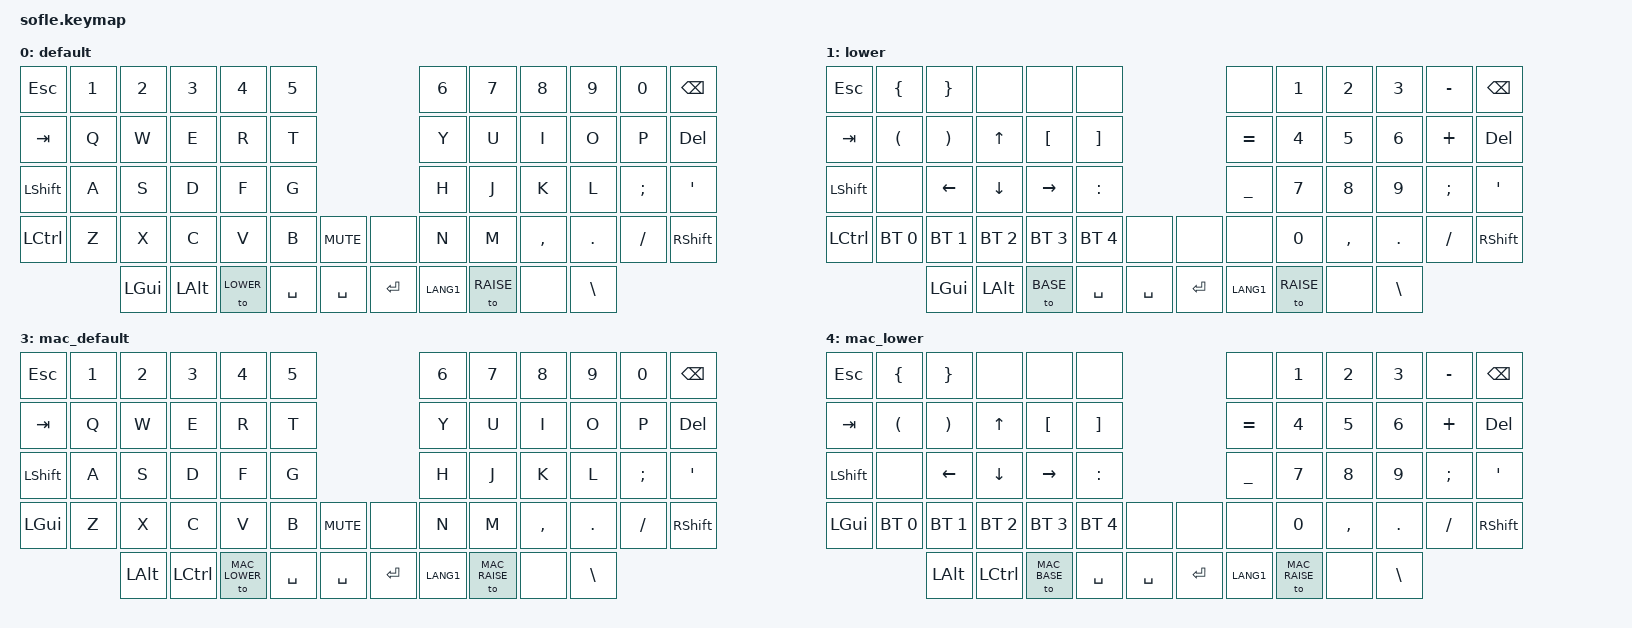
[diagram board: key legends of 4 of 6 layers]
/*
 * Copyright (c) 2020 The ZMK Contributors
 *
 * SPDX-License-Identifier: MIT
 */

#include <behaviors.dtsi>
#include <dt-bindings/zmk/keys.h>
#include <dt-bindings/zmk/bt.h>
#include <dt-bindings/zmk/rgb.h>
#include <dt-bindings/zmk/ext_power.h>

#define BASE 0
#define LOWER 1
#define RAISE 2
#define MAC_BASE 3
#define MAC_LOWER 4
#define MAC_RAISE 5


/ {

   // Activate ADJUST layer by pressing raise and lower
   //conditional_layers {
   //   compatible = "zmk,conditional-layers";
   //   adjust_layer {
   //       if-layers = <LOWER RAISE>;
   //       then-layer = <ADJUST>;
   //   };
   //};

    keymap {
        compatible = "zmk,keymap";

        default_layer {
            display-name = "default";
// ------------------------------------------------------------------------------------------------------------
// |  ESC  |  1  |  2  |  3   |  4   |  5   |                   |  6   |  7    |  8    |  9   |   0   | BKSPC |
// |  TAB  |  Q  |  W  |  E   |  R   |  T   |                   |  Y   |  U    |  I    |  O   |   P   |  DEL  |
// | SHIFT |  A  |  S  |  D   |  F   |  G   |                   |  H   |  J    |  K    |  L   |   ;   |   '   |
// | CTRL  |  Z  |  X  |  C   |  V   |  B   |  MUTE  |  |       |  N   |  M    |  , <  |  . > |   /   | SHIFT |
//               | GUI | ALT  | LOWER| SPACE|  SPACE |  | ENTER | Lang | RAISE |       |  \   |
            bindings = <
&kp ESC   &kp N1 &kp N2   &kp N3   &kp N4    &kp N5                           &kp N6 &kp N7    &kp N8    &kp N9   &kp N0   &kp BSPC
&kp TAB   &kp Q  &kp W    &kp E    &kp R     &kp T                            &kp Y  &kp U     &kp I     &kp O    &kp P    &kp DEL
&kp LSHFT &kp A  &kp S    &kp D    &kp F     &kp G                            &kp H  &kp J     &kp K     &kp L    &kp SEMI &kp SQT
&kp LCTRL &kp Z  &kp X    &kp C    &kp V     &kp B      &kp C_MUTE &none      &kp N  &kp M     &kp COMMA &kp DOT  &kp FSLH &kp RSHFT
                 &kp LGUI &kp LALT &to LOWER &kp SPACE  &kp SPACE  &kp RET    &kp LANG1 &to RAISE &none  &kp BSLH
            >;

            sensor-bindings = <&inc_dec_kp C_VOL_UP C_VOL_DN &inc_dec_kp PG_UP PG_DN>;  
        };

        lower_layer {
            display-name = "lower";
// ------------------------------------------------------------------------------------------------------------
// |  ESC  |  {  |  }  |      |      |      |                   |      |  1    |  2    |  3   |   −   | BKSPC |
// |  TAB  |  (  |  )  |  UP  |  [   |  ]   |                   |  =   |  4    |  5    |  6   |   +   | DEL   |
// | SHIFT |     | LEFT| DOWN |RIGHT |  :   |                   |  _   |  7    |  8    |  9   |   ;   |   '   |
// | CTRL  | BT1 | BT2 | BT3  | BT4  | BT5  |        |  |       |      |  0    |  ,    |  .   |   /   | SHIFT |
//               | GUI | ALT  | BASE | SPACE| SPACE  |  | ENTER | Lang | RAISE |       |  \   |
             bindings = <
&kp ESC    &kp LBRC     &kp RBRC     &none        &none        &none                                &none     &kp N1   &kp N2          &kp N3    &kp MINUS &kp BSPC
&kp TAB    &kp LPAR     &kp RPAR     &kp UP       &kp LBKT     &kp RBKT                             &kp EQUAL &kp N4   &kp N5          &kp N6    &kp PLUS  &kp DEL
&kp LSHFT  &none        &kp LEFT     &kp DOWN     &kp RIGHT    &kp COLON                            &kp UNDER &kp N7   &kp N8          &kp N9    &kp SEMI  &kp SQT
&kp LCTRL  &bt BT_SEL 0 &bt BT_SEL 1 &bt BT_SEL 2 &bt BT_SEL 3 &bt BT_SEL 4   &none  &none          &none     &kp N0   &kp COMMA       &kp DOT   &kp FSLH  &kp RSHFT
                 &kp LGUI &kp LALT &to BASE &kp SPACE  &kp SPACE                          &kp RET   &kp LANG1 &to RAISE&none           &kp BSLH
            >;

            sensor-bindings = <&inc_dec_kp C_VOL_UP C_VOL_DN &inc_dec_kp PG_UP PG_DN>;
        };

        raise_layer {
            display-name = "raise";
// ------------------------------------------------------------------------------------------------------------
// |  ESC  |  F1  |  F2  |  F3   |  F4   |  F5  |                |  F6  |  F7    |  F8   |  F9  |  F10  | BKSPC |
// | CAPS  | INS  | HOME | PGUP  |  F11  |  F12 |                |      |        |       |      |       |  DEL  |
// | SHIFT | DEL  | END  | PGDN  |       |      |                |      |        |       |      |       |       |
// | CTRL  | UNDO | CUT  | COPY  | PASTE |      |      |  |      | BTCLR|MAC BASE|       |      |       |       |
//                | GUI  |  ALT  | LOWER | SPACE| SPACE|  | ENTER| Lang | BASE   |       |      |
            bindings = <
&kp ESC    &kp F1       &kp F2       &kp F3       &kp F4       &kp F5                        &kp F6    &kp F7       &kp F8    &kp F9    &kp F10   &kp BSPC
&kp CAPS   &kp INS      &kp HOME     &kp PGUP     &kp F11      &kp F12                       &none     &none        &none     &none     &none     &kp DEL
&kp LSHFT  &kp DEL      &kp END      &kp PGDN     &none        &none                         &none     &none        &none     &none     &none     &none
&kp LCTRL  &kp K_UNDO   &kp K_CUT    &kp K_COPY   &kp K_PASTE  &none         &none   &none   &bt BT_CLR&to MAC_BASE &none     &none     &none     &none
                        &kp LGUI     &kp LALT     &to LOWER    &kp SPACE   &kp SPACE &kp RET &kp LANG1 &to BASE     &none     &none     &none
            >;

            sensor-bindings = <&inc_dec_kp C_VOL_UP C_VOL_DN &inc_dec_kp PG_UP PG_DN>;
        };



        mac_default_layer {
            display-name = "mac_default";
// ------------------------------------------------------------------------------------------------------------
// |  ESC  |  1  |  2  |  3   |  4   |  5   |                   |  6   |  7    |  8    |  9   |   0   | BKSPC |
// |  TAB  |  Q  |  W  |  E   |  R   |  T   |                   |  Y   |  U    |  I    |  O   |   P   |  DEL  |
// | SHIFT |  A  |  S  |  D   |  F   |  G   |                   |  H   |  J    |  K    |  L   |   ;   |   '   |
// | CTRL  |  Z  |  X  |  C   |  V   |  B   |  MUTE  |  |       |  N   |  M    |  , <  |  . > |   /   | SHIFT |
//               | GUI | ALT  | LOWER| SPACE|  SPACE |  | ENTER | Lang | RAISE |       |  \   |
            bindings = <
&kp ESC   &kp N1 &kp N2   &kp N3   &kp N4    &kp N5                           &kp N6 &kp N7    &kp N8    &kp N9   &kp N0   &kp BSPC
&kp TAB   &kp Q  &kp W    &kp E    &kp R     &kp T                            &kp Y  &kp U     &kp I     &kp O    &kp P    &kp DEL
&kp LSHFT &kp A  &kp S    &kp D    &kp F     &kp G                            &kp H  &kp J     &kp K     &kp L    &kp SEMI &kp SQT
&kp LGUI &kp Z  &kp X    &kp C    &kp V     &kp B      &kp C_MUTE &none      &kp N  &kp M     &kp COMMA &kp DOT  &kp FSLH &kp RSHFT
                 &kp LALT &kp LCTRL &to MAC_LOWER &kp SPACE  &kp SPACE  &kp RET    &kp LANG1 &to MAC_RAISE &none  &kp BSLH
            >;

            sensor-bindings = <&inc_dec_kp C_VOL_UP C_VOL_DN &inc_dec_kp PG_UP PG_DN>;  
        };

        mac_lower_layer {
            display-name = "mac_lower";
// ------------------------------------------------------------------------------------------------------------
// |  ESC  |  {  |  }  |      |      |      |                   |      |  1    |  2    |  3   |   −   | BKSPC |
// |  TAB  |  (  |  )  |  UP  |  [   |  ]   |                   |  =   |  4    |  5    |  6   |   +   | DEL   |
// | SHIFT |     | LEFT| DOWN |RIGHT |  :   |                   |  _   |  7    |  8    |  9   |   ;   |   '   |
// | CTRL  | BT1 | BT2 | BT3  | BT4  | BT5  |        |  |       |      |  0    |  ,    |  .   |   /   | SHIFT |
//               | GUI | ALT  | BASE | SPACE| SPACE  |  | ENTER | Lang | RAISE |       |  \   |
             bindings = <
&kp ESC    &kp LBRC     &kp RBRC     &none        &none        &none                                &none     &kp N1   &kp N2          &kp N3    &kp MINUS &kp BSPC
&kp TAB    &kp LPAR     &kp RPAR     &kp UP       &kp LBKT     &kp RBKT                             &kp EQUAL &kp N4   &kp N5          &kp N6    &kp PLUS  &kp DEL
&kp LSHFT  &none        &kp LEFT     &kp DOWN     &kp RIGHT    &kp COLON                            &kp UNDER &kp N7   &kp N8          &kp N9    &kp SEMI  &kp SQT
&kp LGUI  &bt BT_SEL 0 &bt BT_SEL 1 &bt BT_SEL 2 &bt BT_SEL 3 &bt BT_SEL 4   &none  &none          &none     &kp N0   &kp COMMA       &kp DOT   &kp FSLH  &kp RSHFT
                 &kp LALT &kp LCTRL &to MAC_BASE &kp SPACE  &kp SPACE                          &kp RET   &kp LANG1 &to MAC_RAISE&none           &kp BSLH
            >;

            sensor-bindings = <&inc_dec_kp C_VOL_UP C_VOL_DN &inc_dec_kp PG_UP PG_DN>;
        };

        mac_raise_layer {
            display-name = "mac_raise";
// ------------------------------------------------------------------------------------------------------------
// |  ESC  |  F1  |  F2  |  F3   |  F4   |  F5  |                |  F6  |  F7    |  F8   |  F9  |  F10  | BKSPC |
// | CAPS  | INS  | HOME | PGUP  |  F11  |  F12 |                |      |        |       |      |       |  DEL  |
// | SHIFT | DEL  | END  | PGDN  |       |      |                |      |        |       |      |       |       |
// | CTRL  | UNDO | CUT  | COPY  | PASTE |      |      |  |      | BTCLR|WIN BASE|       |      |       |       |
//                | GUI  |  ALT  | LOWER | SPACE| SPACE|  | ENTER| Lang | BASE   |       |      |
            bindings = <
&kp ESC    &kp F1       &kp F2       &kp F3       &kp F4       &kp F5                        &kp F6    &kp F7       &kp F8    &kp F9    &kp F10   &kp BSPC
&kp CAPS   &kp INS      &kp HOME     &kp PGUP     &kp F11      &kp F12                       &none     &none        &none     &none     &none     &kp DEL
&kp LSHFT  &kp DEL      &kp END      &kp PGDN     &none        &none                         &none     &none        &none     &none     &none     &none
&kp LGUI   &kp K_UNDO   &kp K_CUT    &kp K_COPY   &kp K_PASTE  &none         &none   &none   &bt BT_CLR&to BASE     &none     &none     &none     &none
                        &kp LALT     &kp LCTRL    &to MAC_LOWER    &kp SPACE   &kp SPACE &kp RET &kp LANG1    &to MAC_BASE  &none     &none     &none
            >;

            sensor-bindings = <&inc_dec_kp C_VOL_UP C_VOL_DN &inc_dec_kp PG_UP PG_DN>;
        };




    };
};
